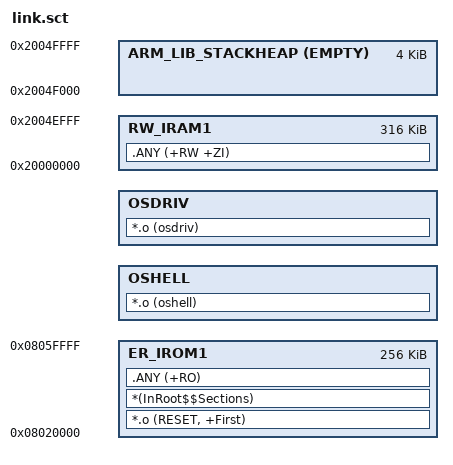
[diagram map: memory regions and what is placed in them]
; *************************************************************
; *** Scatter-Loading Description File generated by uVision ***
; *************************************************************

LR_IROM1 0x08020000 0x00040000  {                   ; load region size_region
    ER_IROM1 0x08020000 0x00040000  {               ; load address = execution address
        *.o (RESET, +First)
        *(InRoot$$Sections)
        .ANY (+RO)
    }
    OSHELL +0 ALIGN 4 { *.o (oshell) }
    OSDRIV +0 ALIGN 4 { *.o (osdriv) }
    RW_IRAM1 0x20000000 0x0004F000  {               ; RW data
        .ANY (+RW +ZI)
    }
    ARM_LIB_STACKHEAP 0x2004F000 EMPTY 0x1000  {    ; LiteOS MSP
    }
}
